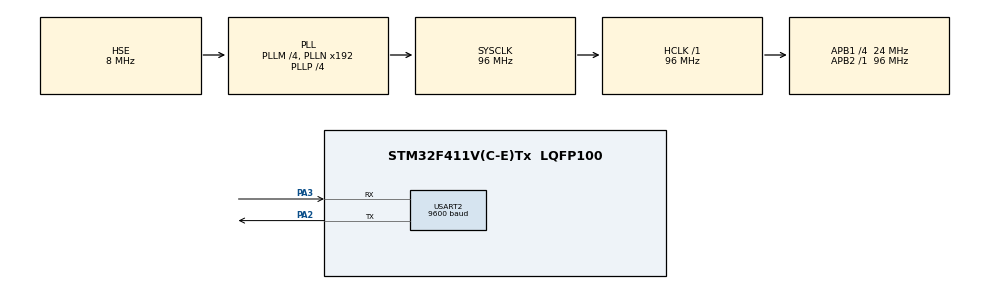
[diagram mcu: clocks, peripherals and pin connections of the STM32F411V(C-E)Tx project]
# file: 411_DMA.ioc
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Mcu.Family=STM32F4
Mcu.Name=STM32F411V(C-E)Tx
Mcu.Package=LQFP100
NVIC.PriorityGroup=NVIC_PRIORITYGROUP_0
PA2.Mode=Asynchronous
PA2.Signal=USART2_TX
PA3.Mode=Asynchronous
PA3.Signal=USART2_RX
PH0\ -\ OSC_IN.Mode=HSE-External-Oscillator
PH0\ -\ OSC_IN.Signal=RCC_OSC_IN
PH1\ -\ OSC_OUT.Mode=HSE-External-Oscillator
PH1\ -\ OSC_OUT.Signal=RCC_OSC_OUT
ProjectManager.HeapSize=0x200
ProjectManager.StackSize=0x400
ProjectManager.TargetToolchain=STM32CubeIDE
RCC.48MHZClocksFreq_Value=48000000
RCC.AHBFreq_Value=96000000
RCC.APB1CLKDivider=RCC_HCLK_DIV4
RCC.APB1Freq_Value=24000000
RCC.APB1TimFreq_Value=48000000
RCC.APB2Freq_Value=96000000
RCC.APB2TimFreq_Value=96000000
RCC.CortexFreq_Value=96000000
RCC.HCLKFreq_Value=96000000
RCC.HSE_VALUE=8000000
RCC.HSI_VALUE=16000000
RCC.LSE_VALUE=32768
RCC.PLLI2SM=5
RCC.PLLI2SN=200
RCC.PLLM=4
RCC.PLLP=RCC_PLLP_DIV4
RCC.PLLQ=8
RCC.PLLSourceVirtual=RCC_PLLSOURCE_HSE
RCC.SYSCLKFreq_VALUE=96000000
RCC.SYSCLKSource=RCC_SYSCLKSOURCE_PLLCLK
RCC.VCOOutputFreq_Value=384000000
USART2.BaudRate=9600
USART2.VirtualMode=VM_ASYNC
board=STM32F411E-DISCO

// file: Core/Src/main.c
/* USER CODE BEGIN Header */
/**
  ******************************************************************************
  * @file           : main.c
  * @brief          : Main program body
  ******************************************************************************
  * @attention
  *
  * Copyright (c) 2024 STMicroelectronics.
  * All rights reserved.
  *
  * This software is licensed under terms that can be found in the LICENSE file
  * in the root directory of this software component.
  * If no LICENSE file comes with this software, it is provided AS-IS.
  *
  ******************************************************************************
  */
/* USER CODE END Header */
#include "main.h"

/* USER CODE BEGIN Includes */
#include "stm32f4xx_hal.h"
/* USER CODE END Includes */

UART_HandleTypeDef huart2;

/* USER CODE BEGIN PV */
#define MEMSIZE 32

/* USER CODE END PV */

void SystemClock_Config(void);
static void MX_GPIO_Init(void);
static void MX_USART2_UART_Init(void);
/* USER CODE BEGIN PFP */
void led_init(void);
/* USER CODE END PFP */

/* USER CODE BEGIN 0 */

// Ganesh Sharma  -- DMA memory to Memory Transfer STM32

 static uint16_t tx_data=65, rx_data=0;
 static uint16_t *tx_p=&tx_data, *rx_p=&rx_data;

/* USER CODE END 0 */

int main(void)
{

  /* MCU Configuration--------------------------------------------------------*/

  /* Reset of all peripherals, Initializes the Flash interface and the Systick. */
  HAL_Init();

  /* USER CODE BEGIN Init */

  	   /* 5 - Enable UART Interrupt in NVIC */

  	    HAL_NVIC_SetPriority(DMA2_Stream0_IRQn, 0, 0);
  	    HAL_NVIC_EnableIRQ(DMA2_Stream0_IRQn);

	//DMA2_Stream0->CR |= DMA_SxCR_CHSEL_0;
	//DMA2_Stream0->CR |= DMA_SxCR_CHSEL_1;
	//DMA2_Stream0->CR |= DMA_SxCR_CHSEL_2;

	//DMA2_Stream0->CR |= DMA_SxCR_PL_0;
	//DMA2_Stream0->CR |= DMA_SxCR_PL_1;

  	//DMA2_Stream0->CR |= DMA_SxCR_MINC;

  	RCC->AHB1ENR |= RCC_AHB1ENR_DMA2EN;

	DMA2_Stream0->CR &= ~(DMA_SxCR_DIR_0);
	DMA2_Stream0->CR |= DMA_SxCR_DIR_1;

	DMA2_Stream0->CR &= ~(DMA_SxCR_MSIZE_0);
	DMA2_Stream0->CR |= DMA_SxCR_MSIZE_1;

	DMA2_Stream0->CR &= ~(DMA_SxCR_PSIZE_0);
	DMA2_Stream0->CR |= DMA_SxCR_PSIZE_1;

	DMA2_Stream0->CR |= DMA_SxCR_CIRC;

	DMA2_Stream0->NDTR = 1;

	DMA2_Stream0->PAR = (uint32_t) tx_p;

	DMA2_Stream0->M0AR = (uint32_t) rx_p;

	DMA2_Stream0->CR |=DMA_SxCR_TCIE;

	DMA2_Stream0->CR |= DMA_SxCR_EN;

	// HAL_Delay(100);
	//HAL_GPIO_WritePin(LED15_GPIO_Port,LED15_Pin,GPIO_PIN_SET);

	/* USER CODE END Init */

	/* Configure the system clock */
	SystemClock_Config();

	/* Initialize all configured peripherals */
	MX_GPIO_Init();
	MX_USART2_UART_Init();
	/* USER CODE BEGIN 2 */

/*uint32_t source[MEMSIZE];
uint32_t dest[MEMSIZE];
uint32_t result;
uint32_t result1=10;*/

    //RCC->AHB1ENR |= RCC_AHB1ENR_DMA2EN; // Enable DMA2 clock

  /*  // Initialize the test data
    for (int i = 20; i < 23; ++i) {
        source[i] = i;
    }

    DMA2_Stream0->CR |= (0b10 << DMA_SxCR_DIR_Pos) // Memory-to-memory Mode
            | (0b01 << DMA_SxCR_PSIZE_Pos) // Source: 16-bit
            | (0b01 << DMA_SxCR_MSIZE_Pos) // Destination: 16-bit
            | DMA_SxCR_PINC // Increment source pointer
            | DMA_SxCR_MINC; // Increment destination pointer
    DMA2_Stream0->PAR = (uint32_t) source;
    DMA2_Stream0->M0AR = (uint32_t) dest;
    DMA2_Stream0->NDTR = 3;

    DMA2_Stream0->CR |= DMA_SxCR_EN; // Start DMA transfer

    while (1) {
        __NOP();
    }*/

  /* USER CODE END 2 */

  /* Infinite loop */
  /* USER CODE BEGIN WHILE */
  while (1)
  {
	  //USART2->DR=65;
	  //HAL_Delay(1000);
    /* USER CODE END WHILE */

  }
}

void SystemClock_Config(void)
{
  RCC_OscInitTypeDef RCC_OscInitStruct = {0};
  RCC_ClkInitTypeDef RCC_ClkInitStruct = {0};

  /** Configure the main internal regulator output voltage
  */
  __HAL_RCC_PWR_CLK_ENABLE();
  __HAL_PWR_VOLTAGESCALING_CONFIG(PWR_REGULATOR_VOLTAGE_SCALE1);

  /** Initializes the RCC Oscillators according to the specified parameters
  * in the RCC_OscInitTypeDef structure.
  */
  RCC_OscInitStruct.OscillatorType = RCC_OSCILLATORTYPE_HSE;
  RCC_OscInitStruct.HSEState = RCC_HSE_ON;
  RCC_OscInitStruct.PLL.PLLState = RCC_PLL_ON;
  RCC_OscInitStruct.PLL.PLLSource = RCC_PLLSOURCE_HSE;
  RCC_OscInitStruct.PLL.PLLM = 4;
  RCC_OscInitStruct.PLL.PLLN = 192;
  RCC_OscInitStruct.PLL.PLLP = RCC_PLLP_DIV4;
  RCC_OscInitStruct.PLL.PLLQ = 8;
  if (HAL_RCC_OscConfig(&RCC_OscInitStruct) != HAL_OK)
  {
    Error_Handler();
  }

  /** Initializes the CPU, AHB and APB buses clocks
  */
  RCC_ClkInitStruct.ClockType = RCC_CLOCKTYPE_HCLK|RCC_CLOCKTYPE_SYSCLK
                              |RCC_CLOCKTYPE_PCLK1|RCC_CLOCKTYPE_PCLK2;
  RCC_ClkInitStruct.SYSCLKSource = RCC_SYSCLKSOURCE_PLLCLK;
  RCC_ClkInitStruct.AHBCLKDivider = RCC_SYSCLK_DIV1;
  RCC_ClkInitStruct.APB1CLKDivider = RCC_HCLK_DIV4;
  RCC_ClkInitStruct.APB2CLKDivider = RCC_HCLK_DIV1;

  if (HAL_RCC_ClockConfig(&RCC_ClkInitStruct, FLASH_LATENCY_3) != HAL_OK)
  {
    Error_Handler();
  }
}

static void MX_USART2_UART_Init(void)
{

  huart2.Instance = USART2;
  huart2.Init.BaudRate = 9600;
  huart2.Init.WordLength = UART_WORDLENGTH_8B;
  huart2.Init.StopBits = UART_STOPBITS_1;
  huart2.Init.Parity = UART_PARITY_NONE;
  huart2.Init.Mode = UART_MODE_TX_RX;
  huart2.Init.HwFlowCtl = UART_HWCONTROL_NONE;
  huart2.Init.OverSampling = UART_OVERSAMPLING_16;
  if (HAL_UART_Init(&huart2) != HAL_OK)
  {
    Error_Handler();
  }

}

static void MX_GPIO_Init(void)
{

  /* GPIO Ports Clock Enable */
  __HAL_RCC_GPIOH_CLK_ENABLE();
  __HAL_RCC_GPIOA_CLK_ENABLE();

}

/* USER CODE BEGIN 4 */

void DMA2_Stream0_IRQHandler(void){
	led_init();
	time1();
	GPIOD->ODR &=~(1 << 15);
	time1();
	DMA2_Stream0->CR &=~(DMA_SxCR_TCIE);
}

void led_init(void){

	RCC->AHB1ENR |= RCC_AHB1ENR_GPIODEN;
	//RCC->AHB1ENR |=(1<<3);

	GPIOD->MODER |= (1 << 30);
	GPIOD->MODER &= ~(1 << 31);
	GPIOD->OTYPER &= ~(1 << 15);
	GPIOD->OSPEEDR |= (1 << 30);
	GPIOD->OSPEEDR &= ~(1 << 31);
	GPIOD->PUPDR &= ~((1 << 30) | (1 << 31));
	GPIOD->ODR |= 1 << 15;

}

void time1(void){
	for (int var = 0; var < 1000000; ++var) {

	}
}

/* USER CODE END 4 */

void Error_Handler(void)
{
  __disable_irq();
  while (1)
  {
  }
}
